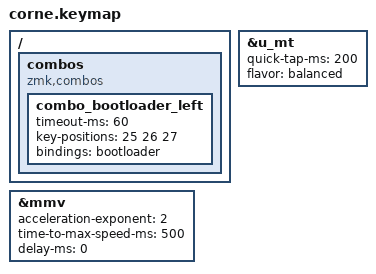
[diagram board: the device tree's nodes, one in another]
// Copyright 2021 Manna Harbour
// https://github.com/manna-harbour/miryoku

#include "../miryoku/custom_config.h"
#include "../miryoku/mapping/42/corne.h"
#include "../miryoku/miryoku.dtsi"

&mmv {
    acceleration-exponent = <2>;
    time-to-max-speed-ms = <500>;
    delay-ms = <0>;
};

&u_mt {
    quick-tap-ms = <200>;
    flavor = "balanced";
};

/ {
    combos {
        compatible = "zmk,combos";

        // 좌측 코네 부트로더 진입 (하단 Z + X + C 동시 누름)
        combo_bootloader_left {
            timeout-ms = <60>;
            key-positions = <25 26 27>; // Z, X, C
            bindings = <&bootloader>;
        };
    };
};
